# GD32F5xx register map
File version: 1.0
CPU: CM33 r0p1, little endian, MPU, FPU, 4 interrupt priority bits
Registers are 32-bit, read-write, reset 0x0 unless marked. A register's access mark holds for its fields unless they carry their own. Offsets are from the block's base; [hi:lo] are bit positions; {n}, {i} and the like mark numbered series.

## DAC — Digital-to-analog converter
Base 0x40007400
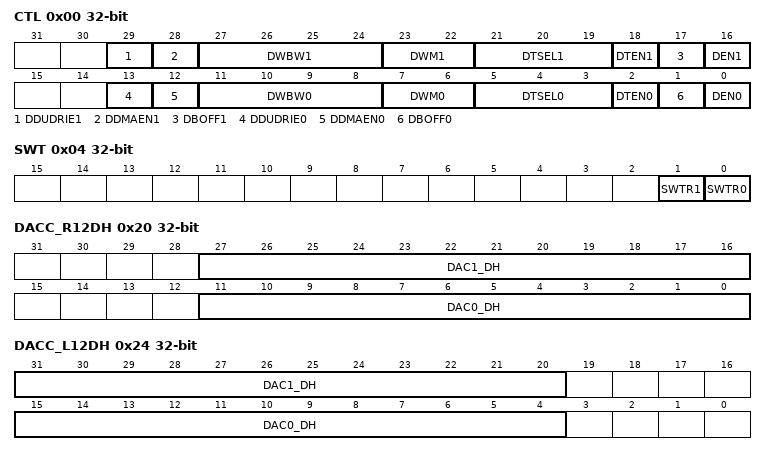
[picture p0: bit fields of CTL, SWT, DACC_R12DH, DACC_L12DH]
0x00 CTL — Control register
  [29] DDUDRIE1 — DAC1 DMA Underrun Interrupt enable
  [28] DDMAEN1 — DAC1 DMA enable
  [27:24] DWBW1 — DAC1 noise wave bit width
  [23:22] DWM1 — DAC1 noise wave mode
  [21:19] DTSEL1 — DAC1 trigger selection
  [18] DTEN1 — DAC1 trigger enable
  [17] DBOFF1 — DAC1 output buffer turn off
  [16] DEN1 — DAC1 enable
  [13] DDUDRIE0 — DAC0 DMA Underrun Interrupt enable
  [12] DDMAEN0 — DAC0 DMA enable
  [11:8] DWBW0 — DAC0 noise wave bit width
  [7:6] DWM0 — DAC0 noise wave mode
  [5:3] DTSEL0 — DAC0 trigger selection
  [2] DTEN0 — DAC0 trigger enable
  [1] DBOFF0 — DAC0 output buffer turn off
  [0] DEN0 — DAC0 enable
0x04 SWT wo — Software trigger register
  [1] SWTR1 — DAC1 software trigger, cleared by hardware
  [0] SWTR0 — DAC0 software trigger, cleared by hardware
0x08 OUT0_R12DH — DAC0 12-bit right-aligned data holding register
  [11:0] DAC0_DH — DAC0 12-bit right-aligned data
0x0C OUT0_L12DH — DAC0 12-bit left-aligned data holding register
  [15:4] DAC0_DH — DAC0 12-bit left-aligned data
0x10 OUT0_R8DH — DAC0 8-bit right-aligned data holding register
  [7:0] DAC0_DH — DAC0 8-bit right-aligned data
0x14 OUT1_R12DH — DAC1 12-bit right-aligned data holding register
  [11:0] DAC1_DH — DAC1 12-bit right-aligned data
0x18 OUT1_L12DH — DAC1 12-bit left-aligned data holding register
  [15:4] DAC1_DH — DAC1 12-bit left-aligned data
0x1C OUT1_R8DH — DAC1 8-bit right-aligned data holding register
  [7:0] DAC1_DH — DAC1 8-bit right-aligned data
0x20 DACC_R12DH — DAC concurrent mode 12-bit right-aligned data holding register
  [27:16] DAC1_DH — DAC1 12-bit right-aligned data
  [11:0] DAC0_DH — DAC0 12-bit right-aligned data
0x24 DACC_L12DH — DAC concurrent mode 12-bit left-aligned data holding register
  [31:20] DAC1_DH — DAC1 12-bit left-aligned data
  [15:4] DAC0_DH — DAC0 12-bit left-aligned data
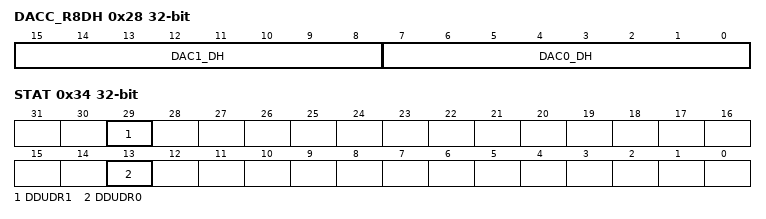
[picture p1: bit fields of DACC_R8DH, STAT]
0x28 DACC_R8DH — DAC concurrent mode 8-bit right-aligned data holding register
  [15:8] DAC1_DH — DAC1 8-bit right-aligned data
  [7:0] DAC0_DH — DAC0 8-bit right-aligned data
0x2C OUT0_DO ro — DAC0 data output register
  [11:0] DAC0_DO — DAC0 data output
0x30 DAC_OUT1_DO ro — DAC1 data output register
  [11:0] DAC1_DO — DAC1 data output
0x34 STAT — Status register
  [29] DDUDR1 — DAC1 DMA underrun flag
  [13] DDUDR0 — DAC0 DMA underrun flag

## DBG — Debug
Base 0xE0044000
0x00 ID ro — ID code register
  [31:0] ID_CODE — DBG ID code register
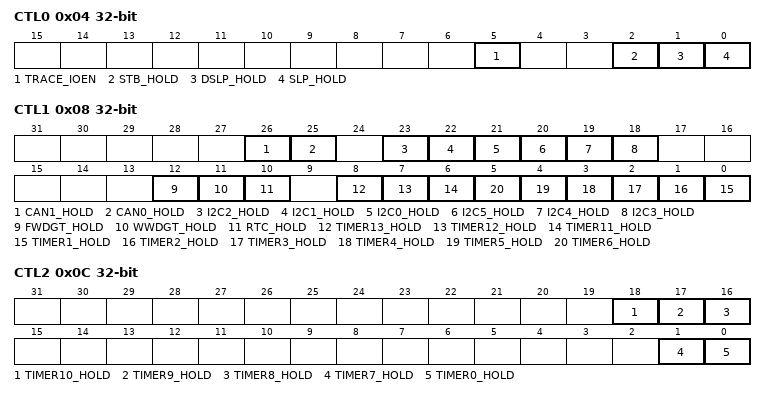
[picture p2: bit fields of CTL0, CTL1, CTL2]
0x04 CTL0 — Control register 0
  [5] TRACE_IOEN — Trace pin allocation enable
  [2] STB_HOLD — Standby mode hold bit
  [1] DSLP_HOLD — Deep-sleep mode hold bit
  [0] SLP_HOLD — Sleep mode hold bit
0x08 CTL1 — Control register 1
  [26] CAN1_HOLD — CAN1 hold bit
  [25] CAN0_HOLD — CAN0 hold bit
  [23] I2C2_HOLD — I2C2 hold bit
  [22] I2C1_HOLD — I2C1 hold bit
  [21] I2C0_HOLD — I2C0 hold bit
  [20] I2C5_HOLD — I2C5 hold bit
  [19] I2C4_HOLD — I2C4 hold bit
  [18] I2C3_HOLD — I2C3 hold bit
  [12] FWDGT_HOLD — FWDGT hold bit
  [11] WWDGT_HOLD — WWDGT hold bit
  [10] RTC_HOLD — RTC hold bit
  [8] TIMER13_HOLD — TIMER 13 hold bit
  [7] TIMER12_HOLD — TIMER 12 hold bit
  [6] TIMER11_HOLD — TIMER 11 hold bit
  [n-1] TIMER{n}_HOLD (n=1..6) — TIMER {n} hold bit
0x0C CTL2 — Control register 2
  [18] TIMER10_HOLD — TIMER 10 hold bit
  [17] TIMER9_HOLD — TIMER 9 hold bit
  [16] TIMER8_HOLD — TIMER 8 hold bit
  [1] TIMER7_HOLD — TIMER 7 hold bit
  [0] TIMER0_HOLD — TIMER 0 hold bit

## DCI — Digital camera interface
Base 0x50050000
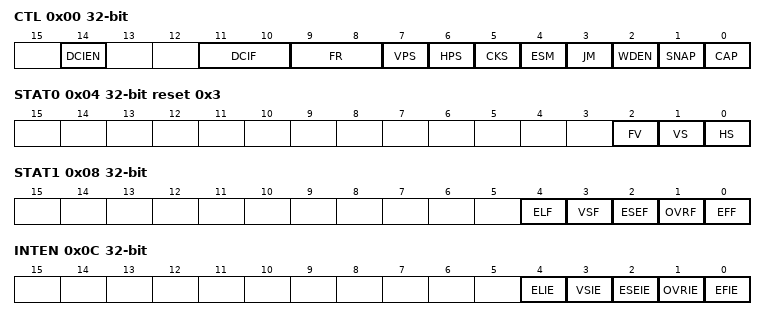
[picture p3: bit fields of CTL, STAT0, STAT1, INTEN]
0x00 CTL — Control register
  [14] DCIEN — DCI Enable
  [11:10] DCIF — Digital Camera Interface Format
  [9:8] FR — Frame Rate
  [7] VPS — Vertical Polarity Selection
  [6] HPS — Horizontal Polarity Selection
  [5] CKS — Clock Polarity Selection
  [4] ESM — Embedded Synchronous Mode
  [3] JM — JPEG Mode
  [2] WDEN — Window Enable
  [1] SNAP — Snapshot Mode
  [0] CAP — Capture Enable
0x04 STAT0 ro reset 0x3 — Status register0
  [2] FV — FIFO Valid
  [1] VS — VS line status
  [0] HS — HS line status
0x08 STAT1 ro — Status register1
  [4] ELF — End of Line Flag
  [3] VSF — Vsync Flag
  [2] ESEF — Embedded Synchronous Error Flag
  [1] OVRF — FIFO Overrun Flag
  [0] EFF — End of Frame Flag
0x0C INTEN — Interrupt enable register
  [4] ELIE — End of Line Interrupt Enable
  [3] VSIE — Vsync Interrupt Enable
  [2] ESEIE — Embedded Synchronous Error Interrupt Enable
  [1] OVRIE — FIFO Overrun Interrupt Enable
  [0] EFIE — End of Frame Interrupt Enable
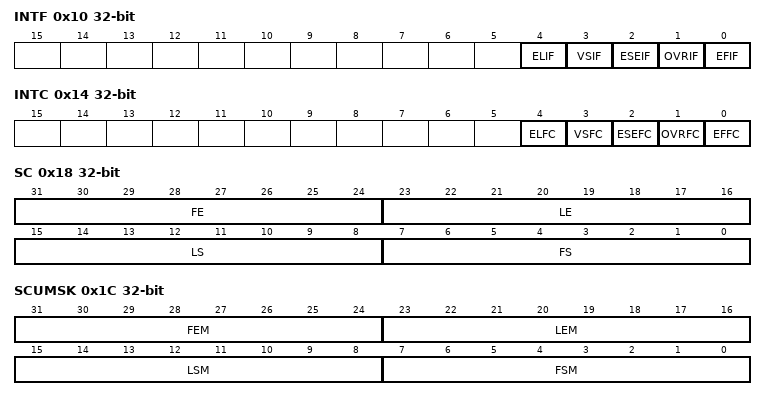
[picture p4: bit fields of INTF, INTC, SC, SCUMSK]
0x10 INTF ro — Interrupt flag register
  [4] ELIF — End of line interrupt flag
  [3] VSIF — Vsync interrupt flag
  [2] ESEIF — Embedded synchronous error interrupt flag
  [1] OVRIF — FIFO overrun interrupt flag
  [0] EFIF — End of frame interrupt flag
0x14 INTC wo — Interrupt flag clear register
  [4] ELFC — End of Line Flag Clear
  [3] VSFC — Vsync flag clear
  [2] ESEFC — Clear embedded synchronous Error Flag
  [1] OVRFC — Clear FIFO Overrun Flag
  [0] EFFC — Clear End of Frame Flag
0x18 SC — Synchronization codes register
  [31:24] FE — Frame end code in embedded synchronous mode
  [23:16] LE — Line end code in embedded synchronous mode
  [15:8] LS — Line start code in embedded synchronous mode
  [7:0] FS — Frame start code in embedded synchronous mode
0x1C SCUMSK — Synchronization codes unmask register
  [31:24] FEM — Frame end code unmask bits in embedded synchronous mode
  [23:16] LEM — Line end code unmask bits in embedded synchronous mode
  [15:8] LSM — Line start code unmask bits in embedded synchronous mode
  [7:0] FSM — Frame start code unmask bits in embedded synchronous mode
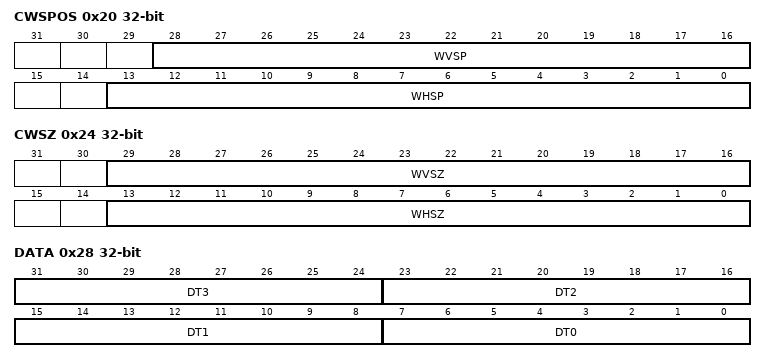
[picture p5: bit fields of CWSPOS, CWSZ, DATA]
0x20 CWSPOS — Cropping window start position register
  [28:16] WVSP — Window Vertical Start Position
  [13:0] WHSP — Window Horizontal Start Position
0x24 CWSZ — Cropping window size register
  [29:16] WVSZ — Window Vertical Size
  [13:0] WHSZ — Window Horizontal Size
0x28 DATA ro
  [8n+7:8n] DT{n} (n=0..3) — Pixel data {n}
